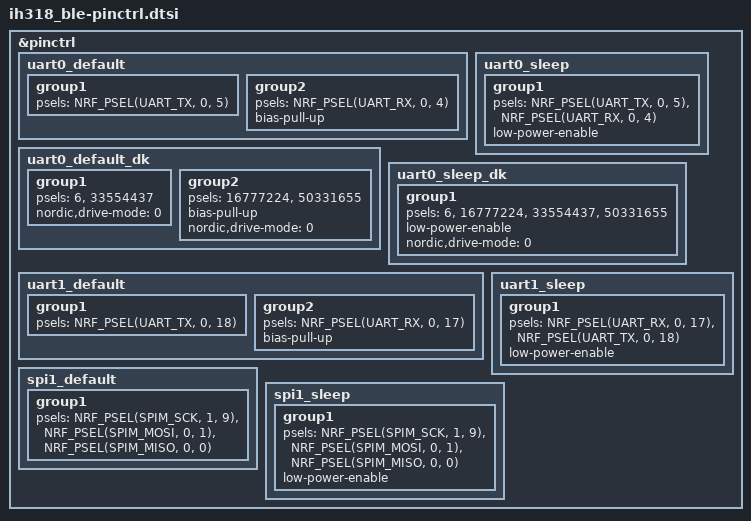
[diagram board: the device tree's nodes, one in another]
/*
 * Copyright (c) 2024 Ihlu
 *
 * SPDX-License-Identifier: Apache-2.0
 */

&pinctrl {

	uart0_default: uart0_default {
		group1 {
			psels = <NRF_PSEL(UART_TX, 0, 5)>;
		};
		group2 {
			psels = <NRF_PSEL(UART_RX, 0, 4)>;
			bias-pull-up;
		};
	};

	uart0_sleep: uart0_sleep {
		group1 {
			psels = <NRF_PSEL(UART_TX, 0, 5)>,
				<NRF_PSEL(UART_RX, 0, 4)>;
			low-power-enable;
		};
	};

	uart0_default_dk: uart0_default_dk {
			group1 {
				psels = <6 /* NRF_PSEL(UART_TX, 0, 6) = 0x6 */>,
					<33554437 /* NRF_PSEL(UART_RTS, 0, 5) = 0x2000005 */>;	/* c:\ncs\v3.2.2\zephyr\boards\nordic\nrf52833dk\nrf52833dk_nrf52833-pinctrl.dtsi */
				nordic,drive-mode = <0 /* 0x0 */>; /* default value from binding */	/* c:\ncs\v3.2.2\zephyr\boards\nordic\nrf52833dk\nrf52833dk_nrf52833-pinctrl.dtsi?loc=7:2-10:4#virtual */
			};

			group2 {
				psels = <16777224 /* NRF_PSEL(UART_RX, 0, 8) = 0x1000008 */>,
					<50331655 /* NRF_PSEL(UART_CTS, 0, 7) = 0x3000007 */>;	/* c:\ncs\v3.2.2\zephyr\boards\nordic\nrf52833dk\nrf52833dk_nrf52833-pinctrl.dtsi */
				bias-pull-up;	/* c:\ncs\v3.2.2\zephyr\boards\nordic\nrf52833dk\nrf52833dk_nrf52833-pinctrl.dtsi */
				nordic,drive-mode = <0 /* 0x0 */>; /* default value from binding */	/* c:\ncs\v3.2.2\zephyr\boards\nordic\nrf52833dk\nrf52833dk_nrf52833-pinctrl.dtsi?loc=12:2-16:4#virtual */
			};
		};

		uart0_sleep_dk: uart0_sleep_dk {
			group1 {
				psels = <6 /* NRF_PSEL(UART_TX, 0, 6) = 0x6 */>,
					<16777224 /* NRF_PSEL(UART_RX, 0, 8) = 0x1000008 */>,
					<33554437 /* NRF_PSEL(UART_RTS, 0, 5) = 0x2000005 */>,
					<50331655 /* NRF_PSEL(UART_CTS, 0, 7) = 0x3000007 */>;	/* c:\ncs\v3.2.2\zephyr\boards\nordic\nrf52833dk\nrf52833dk_nrf52833-pinctrl.dtsi */
				low-power-enable;	/* c:\ncs\v3.2.2\zephyr\boards\nordic\nrf52833dk\nrf52833dk_nrf52833-pinctrl.dtsi */
				nordic,drive-mode = <0 /* 0x0 */>; /* default value from binding */	/* c:\ncs\v3.2.2\zephyr\boards\nordic\nrf52833dk\nrf52833dk_nrf52833-pinctrl.dtsi?loc=20:2-26:4#virtual */
			};
		};

	uart1_default: uart1_default {
		group1 {
			psels = <NRF_PSEL(UART_TX, 0, 18)>;
		};
		group2 {
			psels = <NRF_PSEL(UART_RX, 0, 17)>;
			bias-pull-up;
		};
	};

	uart1_sleep: uart1_sleep {
		group1 {
			psels = <NRF_PSEL(UART_RX, 0, 17)>,
				<NRF_PSEL(UART_TX, 0, 18)>;
			low-power-enable;
		};
	};

	spi1_default: spi1_default {
		group1 {
			psels = <NRF_PSEL(SPIM_SCK, 1, 9)>,
				<NRF_PSEL(SPIM_MOSI, 0, 1)>,
				<NRF_PSEL(SPIM_MISO, 0, 0)>;
		};
	};

	spi1_sleep: spi1_sleep {
		group1 {
			psels = <NRF_PSEL(SPIM_SCK, 1, 9)>,
				<NRF_PSEL(SPIM_MOSI, 0, 1)>,
				<NRF_PSEL(SPIM_MISO, 0, 0)>;
			low-power-enable;
		};
	};
};
